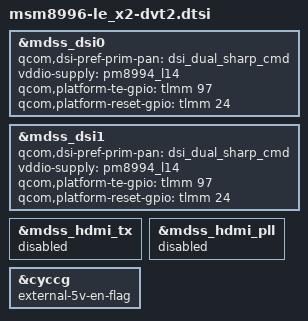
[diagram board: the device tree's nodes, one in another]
#include "msm8996-le_x2-dvt1.1.dtsi"

&mdss_dsi0 {
	qcom,dsi-pref-prim-pan = <&dsi_dual_sharp_cmd>;
	vddio-supply = <&pm8994_l14>;
	qcom,platform-te-gpio = <&tlmm 97 0>;
	qcom,platform-reset-gpio = <&tlmm 24 0>;
	/delete-property/ qcom,platform-bklight-en-gpio;
};

&mdss_dsi1 {
	qcom,dsi-pref-prim-pan = <&dsi_dual_sharp_cmd>;
	vddio-supply = <&pm8994_l14>;
	qcom,platform-te-gpio = <&tlmm 97 0>;
	qcom,platform-reset-gpio = <&tlmm 24 0>;
	/delete-property/ qcom,platform-bklight-en-gpio;
};

/*
&mdss_dsi1 {
	status = "disabled";
};
*/

&mdss_hdmi_tx {
	status = "disabled";
};

&mdss_hdmi_pll {
	/*lyb@bsp 11/17/15: 15801 never VDD_HDMI(L12/L28)*/
	status = "disabled";
};


&cyccg {
	external-5v-en-flag;
};
